# ESP32S31_RADIO register map
Vendor: Espressif; Series: ESP32-S31; File version: 3.52
Registers are 32-bit, read-write, no defined reset value unless marked. A register's access mark holds for its fields unless they carry their own. Offsets are from the block's base; [hi:lo] are bit positions; {n}, {i} and the like mark numbered series; <NAME> marks a mode.

## SHARED_BASEBAND_RESET_IDLE_STATUS — One independently bounded shared-baseband reset-idle status word. The complete Bluetooth bbmac_idle_for_swrst leaf proves the exact predicate, but its location inside another protocol aperture prevents Bluetooth-exclusive ownership.
Base 0x20103088
0x00 STATUS ro — Project-assigned name. bbmac_idle_for_swrst requires the observed low four-bit field to be zero before reporting idle.
  [3:0] TXRX_STATE — The reset-idle predicate fails when this exact field is nonzero.

## SHARED_BASEBAND_TX_TIMING — One physical baseband timing word reached by the common BTBB initializer. The named vendor leaf carries a historical Zigbee prefix, but the current evidence proves only the exact shared initialization transaction and does not grant protocol-exclusive ownership.
Base 0x20102010
0x00 AUXILIARY_TX_ON_DELAY — Project-assigned name. The complete named setter replaces bits 16:26 with an encoded argument image and preserves every other bit.
  [26:16] ENCODED_IMAGE — Project-assigned name. The setter stores ((argument - 10) << 3) in this eleven-bit field; its low three bits therefore become zero.

## BTDM_SCHEDULER_TABLE — Sixteen-entry scheduler hardware-list table. Complete current insertion-begin, insertion-end and lifecycle bodies prove the finite entry count, 0x10-byte stride and low-20-bit compressed SRAM head. Same-chip public named header accessors independently establish the hardware-list role. The upper twelve bits and the unobserved words inside each stride remain unknown.
Base 0x2010B000
{0x0+0x10*i} ENTRY{i} (i=0..15) — Project-assigned name. Scheduler hardware-list entry. Bits 0..19 hold a compressed SRAM head and bits 20..31 remain unassigned.
  [19:0] HEAD_POINTER — Project-assigned name. Compressed four-byte-aligned 0x2f-prefixed SRAM hardware-list head. Zero denotes no published head.

## BLE_HW_POSITIONAL_WORD_1FF0 — Narrow owner for the otherwise unbounded word at 0x20101FF0. Complete ESP32-S31 BLE PHY initialization writes complete image zero followed by complete image one before touching any other radio register. The same ordered writes appear at the same block offset in the named ESP32-C61 counterpart, but neither artifact proves this word's hardware action or membership in the adjacent BTMAC dump range. No wider peripheral extent is claimed.
Base 0x20101FF0
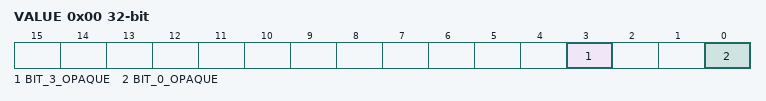
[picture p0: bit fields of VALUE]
0x00 VALUE wo — Project-assigned name. Complete ordered images zero then one at BLE PHY register-initialization entry; their hardware meaning remains unknown.
  [3] BIT_3_OPAQUE — Opaque: meaning not established. Observed source use; the individual hardware meaning is unknown.
  [0] BIT_0_OPAQUE — Opaque: meaning not established. Observed source use; the individual hardware meaning is unknown.

## BLE_HW_POSITIONAL_WORD_891C — Narrow owner for the otherwise isolated word at 0x2010891C. Complete ESP32-S31 BLE PHY initialization writes complete image 0x20 before initializing the BLE hardware accelerator and complete image 0x40 after the surrounding BTMAC and accelerator sequence. The register's physical block, hardware action and the meanings of the two images remain unproved, so no neighboring 0x201088xx words are absorbed.
Base 0x2010891C
0x00 VALUE wo — Project-assigned name. Complete ordered images 0x20 then 0x40 around BLE accelerator initialization; their hardware meaning remains unknown.
  [6:5] BITS_5_6_OPAQUE — Opaque: meaning not established. Observed source use; the individual hardware meaning is unknown.

## BLE_CONTROLLER_ADDRESS_SLOTS — Three positional six-byte controller address slots. A complete ESP32-S31 ble_phy.c leaf proves the selector range, pair stride, byte packing and write order. Named callers identify public-address use of slot zero and random-address use of slot one; slot two remains intentionally unnamed.
Base 0x2010180C
{0x0+8i} SLOT{i}_LOW (i=0..2) wo — Project-assigned name. Bytes zero through three of the selected six-byte value, packed in little-endian order and written before the paired high word.
  [31:0] OCTETS_0_TO_3 — Project-assigned name. The complete low word assembled from input bytes zero through three.
{0x4+8i} SLOT{i}_HIGH (i=0..2) wo — Project-assigned name. Bytes four and five of the selected six-byte value in bits 0..15; the complete write clears bits 16..31.
  [15:0] OCTETS_4_TO_5 — Project-assigned name. Input bytes four and five packed in little-endian order.
